# ESP32-C2 register map
Vendor: ESPRESSIF SYSTEMS (SHANGHAI) CO., LTD.; Series: ESP32 C-Series; File version: 11
CPU: RV32IMC r0p0, little endian, no MPU, no FPU, 0 interrupt priority bits
Address unit: 32 bits
Registers are 32-bit, read-write, reset 0x0 unless marked. A register's access mark holds for its fields unless they carry their own. Offsets are from the block's base; [hi:lo] are bit positions; {n}, {i} and the like mark numbered series.

## RTC_CNTL — Real-Time Clock Control
Base 0x60008000
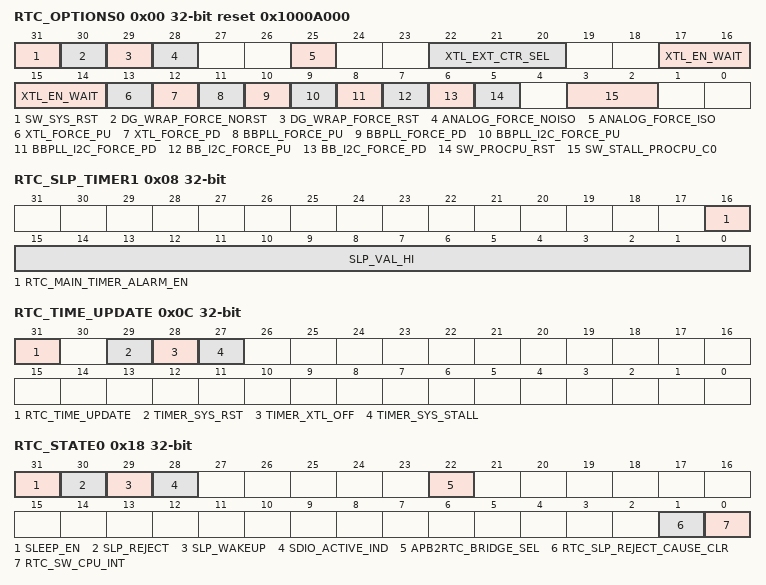
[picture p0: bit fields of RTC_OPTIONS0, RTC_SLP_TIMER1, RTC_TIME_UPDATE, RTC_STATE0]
0x00 RTC_OPTIONS0 reset 0x1000A000 — register description
  [31] SW_SYS_RST — SW system reset
  [30] DG_WRAP_FORCE_NORST — digital core force no reset in deep sleep
  [29] DG_WRAP_FORCE_RST — digital wrap force reset in deep sleep
  [28] ANALOG_FORCE_NOISO — Need add desc
  [25] ANALOG_FORCE_ISO — Need add desc
  [22:20] XTL_EXT_CTR_SEL — Need add desc
  [17:14] XTL_EN_WAIT — wait bias_sleep and current source wakeup
  [13] XTL_FORCE_PU — crystall force power up
  [12] XTL_FORCE_PD — crystall force power down
  [11] BBPLL_FORCE_PU — BB_PLL force power up
  [10] BBPLL_FORCE_PD — BB_PLL force power down
  [9] BBPLL_I2C_FORCE_PU — BB_PLL_I2C force power up
  [8] BBPLL_I2C_FORCE_PD — BB_PLL _I2C force power down
  [7] BB_I2C_FORCE_PU — BB_I2C force power up
  [6] BB_I2C_FORCE_PD — BB_I2C force power down
  [5] SW_PROCPU_RST — PRO CPU SW reset
  [3:2] SW_STALL_PROCPU_C0 — {reg_sw_stall_procpu_c1[5:0], reg_sw_stall_procpu_c0[1:0]} == 0x86 will stall PRO CPU
0x04 RTC_SLP_TIMER0 — register description
  [31:0] SLP_VAL_LO — Need add desc
0x08 RTC_SLP_TIMER1 — register description
  [16] RTC_MAIN_TIMER_ALARM_EN — timer alarm enable bit
  [15:0] SLP_VAL_HI — RTC sleep timer high 16 bits
0x0C RTC_TIME_UPDATE — register description
  [31] RTC_TIME_UPDATE — Set 1: to update register with RTC timer
  [29] TIMER_SYS_RST — enable to record system reset time
  [28] TIMER_XTL_OFF — Enable to record 40M XTAL OFF time
  [27] TIMER_SYS_STALL — Enable to record system stall time
0x10 RTC_TIME_LOW0 — register description
  [31:0] RTC_TIMER_VALUE0_LOW — RTC timer low 32 bits
0x14 RTC_TIME_HIGH0 — register description
  [15:0] RTC_TIMER_VALUE0_HIGH — RTC timer high 16 bits
0x18 RTC_STATE0 — register description
  [31] SLEEP_EN — sleep enable bit
  [30] SLP_REJECT — leep reject bit
  [29] SLP_WAKEUP — leep wakeup bit
  [28] SDIO_ACTIVE_IND — SDIO active indication
  [22] APB2RTC_BRIDGE_SEL — 1: APB to RTC using bridge
  [1] RTC_SLP_REJECT_CAUSE_CLR — clear rtc sleep reject cause
  [0] RTC_SW_CPU_INT — rtc software interrupt to main cpu
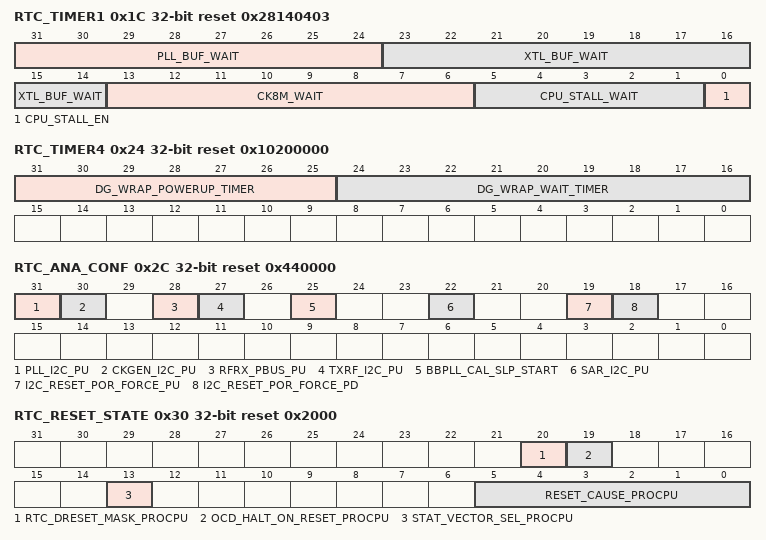
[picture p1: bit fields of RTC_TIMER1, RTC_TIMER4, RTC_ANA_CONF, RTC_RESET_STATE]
0x1C RTC_TIMER1 reset 0x28140403 — register description
  [31:24] PLL_BUF_WAIT — PLL wait cycles in slow_clk_rtc
  [23:14] XTL_BUF_WAIT — XTAL wait cycles in slow_clk_rtc
  [13:6] CK8M_WAIT — CK8M wait cycles in slow_clk_rtc
  [5:1] CPU_STALL_WAIT — CPU stall wait cycles in fast_clk_rtc
  [0] CPU_STALL_EN — CPU stall enable bit
0x20 RTC_TIMER2 reset 0x1000000 — register description
  [31:24] MIN_TIME_CK8M_OFF — minimal cycles in slow_clk_rtc for CK8M in power down state
0x24 RTC_TIMER4 reset 0x10200000 — register description
  [31:25] DG_WRAP_POWERUP_TIMER — Need add desc
  [24:16] DG_WRAP_WAIT_TIMER — Need add desc
0x28 RTC_TIMER5 reset 0x8000 — register description
  [15:8] MIN_SLP_VAL — minimal sleep cycles in slow_clk_rtc
0x2C RTC_ANA_CONF reset 0x440000 — register description
  [31] PLL_I2C_PU — Need add desc
  [30] CKGEN_I2C_PU — 1: CKGEN_I2C power up
  [28] RFRX_PBUS_PU — 1: RFRX_PBUS power up
  [27] TXRF_I2C_PU — 1: TXRF_I2C power up
  [25] BBPLL_CAL_SLP_START — start BBPLL calibration during sleep
  [22] SAR_I2C_PU — PLLA force power up
  [19] I2C_RESET_POR_FORCE_PU — Need add desc
  [18] I2C_RESET_POR_FORCE_PD — Need add desc
0x30 RTC_RESET_STATE reset 0x2000 — register description
  [20] RTC_DRESET_MASK_PROCPU — Need add desc
  [19] OCD_HALT_ON_RESET_PROCPU — PROCPU OcdHaltOnReset
  [13] STAT_VECTOR_SEL_PROCPU — PRO CPU state vector sel
  [5:0] RESET_CAUSE_PROCPU — reset cause of PRO CPU
0x34 RTC_WAKEUP_STATE reset 0x60000 — register description
  [31:15] RTC_WAKEUP_ENA — wakeup enable bitmap
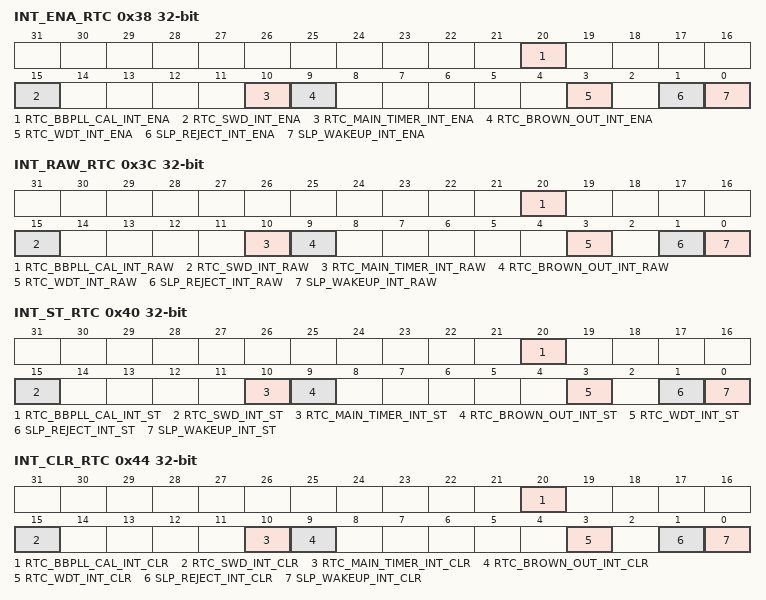
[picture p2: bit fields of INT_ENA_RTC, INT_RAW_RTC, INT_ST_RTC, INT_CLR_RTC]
0x38 INT_ENA_RTC access not given — register description
  [20] RTC_BBPLL_CAL_INT_ENA — Need add desc
  [15] RTC_SWD_INT_ENA — enable super watch dog interrupt
  [10] RTC_MAIN_TIMER_INT_ENA — enable RTC main timer interrupt
  [9] RTC_BROWN_OUT_INT_ENA — enable brown out interrupt
  [3] RTC_WDT_INT_ENA — enable RTC WDT interrupt
  [1] SLP_REJECT_INT_ENA — enable sleep reject interrupt
  [0] SLP_WAKEUP_INT_ENA — enable sleep wakeup interrupt
0x3C INT_RAW_RTC — register description
  [20] RTC_BBPLL_CAL_INT_RAW — Need add desc
  [15] RTC_SWD_INT_RAW — super watch dog interrupt raw
  [10] RTC_MAIN_TIMER_INT_RAW — RTC main timer interrupt raw
  [9] RTC_BROWN_OUT_INT_RAW — brown out interrupt raw
  [3] RTC_WDT_INT_RAW — RTC WDT interrupt raw
  [1] SLP_REJECT_INT_RAW — sleep reject interrupt raw
  [0] SLP_WAKEUP_INT_RAW — sleep wakeup interrupt raw
0x40 INT_ST_RTC — register description
  [20] RTC_BBPLL_CAL_INT_ST — Need add desc
  [15] RTC_SWD_INT_ST — super watch dog interrupt state
  [10] RTC_MAIN_TIMER_INT_ST — RTC main timer interrupt state
  [9] RTC_BROWN_OUT_INT_ST — brown out interrupt state
  [3] RTC_WDT_INT_ST — RTC WDT interrupt state
  [1] SLP_REJECT_INT_ST — sleep reject interrupt state
  [0] SLP_WAKEUP_INT_ST — sleep wakeup interrupt state
0x44 INT_CLR_RTC — register description
  [20] RTC_BBPLL_CAL_INT_CLR — Need add desc
  [15] RTC_SWD_INT_CLR — Clear super watch dog interrupt state
  [10] RTC_MAIN_TIMER_INT_CLR — Clear RTC main timer interrupt state
  [9] RTC_BROWN_OUT_INT_CLR — Clear brown out interrupt state
  [3] RTC_WDT_INT_CLR — Clear RTC WDT interrupt state
  [1] SLP_REJECT_INT_CLR — Clear sleep reject interrupt state
  [0] SLP_WAKEUP_INT_CLR — Clear sleep wakeup interrupt state
{0x48+4i} RTC_STORE{i} (i=0..3) — register description
  [31:0] RTC_SCRATCH{i} — Need add desc
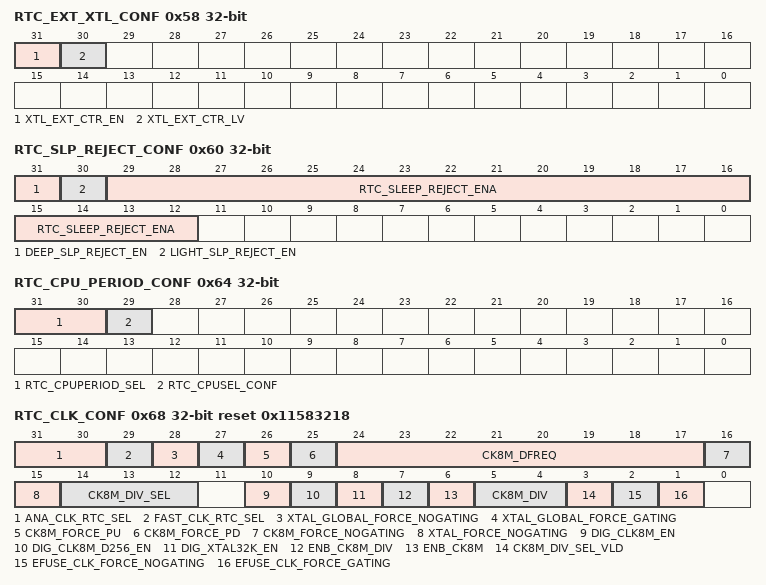
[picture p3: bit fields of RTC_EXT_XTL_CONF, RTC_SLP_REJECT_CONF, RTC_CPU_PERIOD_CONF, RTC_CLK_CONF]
0x58 RTC_EXT_XTL_CONF — register description
  [31] XTL_EXT_CTR_EN — Need add desc
  [30] XTL_EXT_CTR_LV — 0: power down XTAL at high level
0x5C RTC_EXT_WAKEUP_CONF — register description
  [31] GPIO_WAKEUP_FILTER — enable filter for gpio wakeup event
0x60 RTC_SLP_REJECT_CONF — register description
  [31] DEEP_SLP_REJECT_EN — enable reject for deep sleep
  [30] LIGHT_SLP_REJECT_EN — enable reject for light sleep
  [29:12] RTC_SLEEP_REJECT_ENA — sleep reject enable
0x64 RTC_CPU_PERIOD_CONF — register description
  [31:30] RTC_CPUPERIOD_SEL — Need add desc
  [29] RTC_CPUSEL_CONF — CPU sel option
0x68 RTC_CLK_CONF reset 0x11583218 — register description
  [31:30] ANA_CLK_RTC_SEL — Need add desc
  [29] FAST_CLK_RTC_SEL — fast_clk_rtc sel. 0: XTAL div 4
  [28] XTAL_GLOBAL_FORCE_NOGATING — Need add desc
  [27] XTAL_GLOBAL_FORCE_GATING — Need add desc
  [26] CK8M_FORCE_PU — CK8M force power up
  [25] CK8M_FORCE_PD — CK8M force power down
  [24:17] CK8M_DFREQ
  [16] CK8M_FORCE_NOGATING — CK8M force no gating during sleep
  [15] XTAL_FORCE_NOGATING — XTAL force no gating during sleep
  [14:12] CK8M_DIV_SEL — divider = reg_ck8m_div_sel + 1
  [10] DIG_CLK8M_EN — enable CK8M for digital core (no relationship with RTC core)
  [9] DIG_CLK8M_D256_EN — enable CK8M_D256_OUT for digital core (no relationship with RTC core)
  [8] DIG_XTAL32K_EN — enable CK_XTAL_32K for digital core (no relationship with RTC core)
  [7] ENB_CK8M_DIV — 1: CK8M_D256_OUT is actually CK8M
  [6] ENB_CK8M — disable CK8M and CK8M_D256_OUT
  [5:4] CK8M_DIV — CK8M_D256_OUT divider. 00: div128
  [3] CK8M_DIV_SEL_VLD — used to sync reg_ck8m_div_sel bus. Clear vld before set reg_ck8m_div_sel
  [2] EFUSE_CLK_FORCE_NOGATING — Need add desc
  [1] EFUSE_CLK_FORCE_GATING — Need add desc
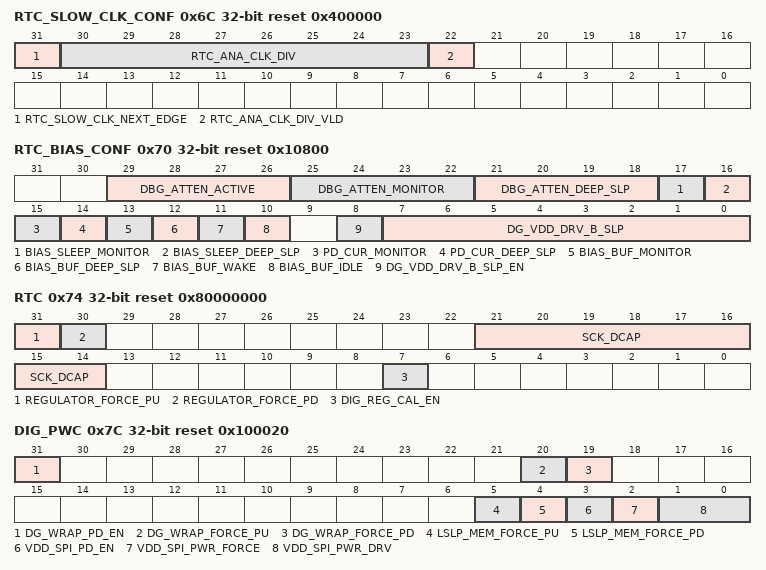
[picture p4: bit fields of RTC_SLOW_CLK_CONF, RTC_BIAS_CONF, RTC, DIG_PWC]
0x6C RTC_SLOW_CLK_CONF reset 0x400000 — register description
  [31] RTC_SLOW_CLK_NEXT_EDGE — Need add desc
  [30:23] RTC_ANA_CLK_DIV — Need add desc
  [22] RTC_ANA_CLK_DIV_VLD — used to sync div bus. clear vld before set reg_rtc_ana_clk_div
0x70 RTC_BIAS_CONF reset 0x10800 — register description
  [29:26] DBG_ATTEN_ACTIVE — Need add desc
  [25:22] DBG_ATTEN_MONITOR — DBG_ATTEN when rtc in active state
  [21:18] DBG_ATTEN_DEEP_SLP — DBG_ATTEN when rtc in sleep state
  [17] BIAS_SLEEP_MONITOR — bias_sleep when rtc in monitor state
  [16] BIAS_SLEEP_DEEP_SLP — bias_sleep when rtc in sleep_state
  [15] PD_CUR_MONITOR — xpd cur when rtc in monitor state
  [14] PD_CUR_DEEP_SLP — xpd cur when rtc in sleep_state
  [13] BIAS_BUF_MONITOR — Need add desc
  [12] BIAS_BUF_DEEP_SLP — Need add desc
  [11] BIAS_BUF_WAKE — Need add desc
  [10] BIAS_BUF_IDLE — Need add desc
  [8] DG_VDD_DRV_B_SLP_EN — Need add desc
  [7:0] DG_VDD_DRV_B_SLP — Need add desc
0x74 RTC reset 0x80000000 — register description
  [31] REGULATOR_FORCE_PU — Need add desc
  [30] REGULATOR_FORCE_PD — RTC_REG force power down (for RTC_REG power down means decrease the voltage to 0.8v or lower )
  [21:14] SCK_DCAP
  [7] DIG_REG_CAL_EN — Need add desc
0x78 RTC_PWC — register description
  [21] RTC_PAD_FORCE_HOLD
0x7C DIG_PWC reset 0x100020 — register description
  [31] DG_WRAP_PD_EN — Need add desc
  [20] DG_WRAP_FORCE_PU — digital core force power up
  [19] DG_WRAP_FORCE_PD — digital core force power down
  [5] LSLP_MEM_FORCE_PU — memories in digital core force no PD in sleep
  [4] LSLP_MEM_FORCE_PD — memories in digital core force PD in sleep
  [3] VDD_SPI_PD_EN — Need add desc
  [2] VDD_SPI_PWR_FORCE — Need add desc
  [1:0] VDD_SPI_PWR_DRV — Need add desc
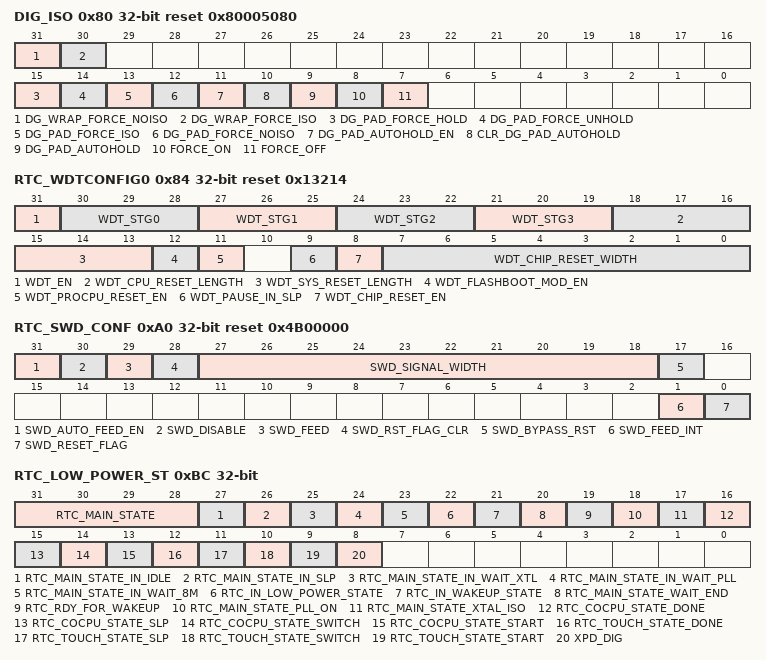
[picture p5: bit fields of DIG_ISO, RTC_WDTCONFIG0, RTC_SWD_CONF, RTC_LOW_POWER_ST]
0x80 DIG_ISO reset 0x80005080 — register description
  [31] DG_WRAP_FORCE_NOISO — Need add desc
  [30] DG_WRAP_FORCE_ISO — digital core force ISO
  [15] DG_PAD_FORCE_HOLD — digital pad force hold
  [14] DG_PAD_FORCE_UNHOLD — digital pad force un-hold
  [13] DG_PAD_FORCE_ISO — digital pad force ISO
  [12] DG_PAD_FORCE_NOISO — digital pad force no ISO
  [11] DG_PAD_AUTOHOLD_EN — digital pad enable auto-hold
  [10] CLR_DG_PAD_AUTOHOLD — wtite only register to clear digital pad auto-hold
  [9] DG_PAD_AUTOHOLD — read only register to indicate digital pad auto-hold status
  [8] FORCE_ON — Need add desc
  [7] FORCE_OFF — Need add desc
0x84 RTC_WDTCONFIG0 reset 0x13214 — register description
  [31] WDT_EN — Need add desc
  [30-3n:28-3n] WDT_STG{n} (n=0..3) — 1: interrupt stage en
  [18:16] WDT_CPU_RESET_LENGTH — CPU reset counter length
  [15:13] WDT_SYS_RESET_LENGTH — system reset counter length
  [12] WDT_FLASHBOOT_MOD_EN — enable WDT in flash boot
  [11] WDT_PROCPU_RESET_EN — enable WDT reset PRO CPU
  [9] WDT_PAUSE_IN_SLP — pause WDT in sleep
  [8] WDT_CHIP_RESET_EN — wdt reset whole chip enable
  [7:0] WDT_CHIP_RESET_WIDTH — chip reset siginal pulse width
0x88 RTC_WDTCONFIG1 reset 0x30D40 — register description
  [31:0] WDT_STG0_HOLD — Need add desc
0x8C RTC_WDTCONFIG2 reset 0x13880 — register description
  [31:0] WDT_STG1_HOLD — Need add desc
0x90 RTC_WDTCONFIG3 reset 0xFFF — register description
  [31:0] WDT_STG2_HOLD — Need add desc
0x94 RTC_WDTCONFIG4 reset 0xFFF — register description
  [31:0] WDT_STG3_HOLD — Need add desc
0x98 RTC_WDTFEED — register description
  [31] RTC_WDT_FEED — Need add desc
0x9C RTC_WDTWPROTECT — register description
  [31:0] WDT_WKEY — Need add desc
0xA0 RTC_SWD_CONF reset 0x4B00000 — register description
  [31] SWD_AUTO_FEED_EN — automatically feed swd when int comes
  [30] SWD_DISABLE — disabel SWD
  [29] SWD_FEED — Sw feed swd
  [28] SWD_RST_FLAG_CLR — reset swd reset flag
  [27:18] SWD_SIGNAL_WIDTH — adjust signal width send to swd
  [17] SWD_BYPASS_RST — Need add desc
  [1] SWD_FEED_INT — swd interrupt for feeding
  [0] SWD_RESET_FLAG
0xA4 RTC_SWD_WPROTECT — register description
  [31:0] SWD_WKEY — Need add desc
0xA8 RTC_SW_CPU_STALL — register description
  [31:26] SW_STALL_PROCPU_C1 — Need add desc
{0x9C+4i} RTC_STORE{i} (i=4..7) — register description
  [31:0] RTC_SCRATCH{i} — Need add desc
0xBC RTC_LOW_POWER_ST — register description
  [31:28] RTC_MAIN_STATE — rtc main state machine status
  [27] RTC_MAIN_STATE_IN_IDLE — rtc main state machine is in idle state
  [26] RTC_MAIN_STATE_IN_SLP — rtc main state machine is in sleep state
  [25] RTC_MAIN_STATE_IN_WAIT_XTL — rtc main state machine is in wait xtal state
  [24] RTC_MAIN_STATE_IN_WAIT_PLL — rtc main state machine is in wait pll state
  [23] RTC_MAIN_STATE_IN_WAIT_8M — rtc main state machine is in wait 8m state
  [22] RTC_IN_LOW_POWER_STATE — rtc main state machine is in the states of low power
  [21] RTC_IN_WAKEUP_STATE — rtc main state machine is in the states of wakeup process
  [20] RTC_MAIN_STATE_WAIT_END — rtc main state machine has been waited for some cycles
  [19] RTC_RDY_FOR_WAKEUP — rtc is ready to receive wake up trigger from wake up source
  [18] RTC_MAIN_STATE_PLL_ON — rtc main state machine is in states that pll should be running
  [17] RTC_MAIN_STATE_XTAL_ISO — no use any more
  [16] RTC_COCPU_STATE_DONE — ulp/cocpu is done
  [15] RTC_COCPU_STATE_SLP — ulp/cocpu is in sleep state
  [14] RTC_COCPU_STATE_SWITCH — ulp/cocpu is about to working. Switch rtc main state
  [13] RTC_COCPU_STATE_START — ulp/cocpu should start to work
  [12] RTC_TOUCH_STATE_DONE — touch is done
  [11] RTC_TOUCH_STATE_SLP — touch is in sleep state
  [10] RTC_TOUCH_STATE_SWITCH — touch is about to working. Switch rtc main state
  [9] RTC_TOUCH_STATE_START — touch should start to work
  [8] XPD_DIG — digital wrap power down
0xC0 RTC_DIAG0 — register description
  [31:0] RTC_LOW_POWER_DIAG1 — Need add desc
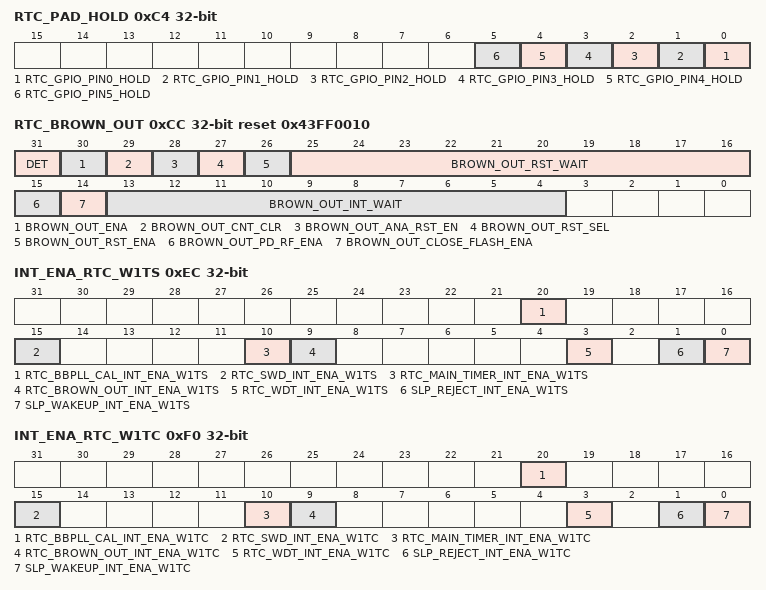
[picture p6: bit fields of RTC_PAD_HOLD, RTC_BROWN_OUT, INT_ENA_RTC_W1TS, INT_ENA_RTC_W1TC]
0xC4 RTC_PAD_HOLD — register description
  [n] RTC_GPIO_PIN{n}_HOLD (n=0..5) — Need add desc
0xC8 DIG_PAD_HOLD — register description
  [31:0] DIG_PAD_HOLD — Need add desc
0xCC RTC_BROWN_OUT reset 0x43FF0010 — register description
  [31] DET — Need add desc
  [30] BROWN_OUT_ENA — enable brown out
  [29] BROWN_OUT_CNT_CLR — clear brown out counter
  [28] BROWN_OUT_ANA_RST_EN — Need add desc
  [27] BROWN_OUT_RST_SEL — 1: 4-pos reset
  [26] BROWN_OUT_RST_ENA — enable brown out reset
  [25:16] BROWN_OUT_RST_WAIT — brown out reset wait cycles
  [15] BROWN_OUT_PD_RF_ENA — enable power down RF when brown out happens
  [14] BROWN_OUT_CLOSE_FLASH_ENA — enable close flash when brown out happens
  [13:4] BROWN_OUT_INT_WAIT — brown out interrupt wait cycles
0xD0 RTC_TIME_LOW1 — register description
  [31:0] RTC_TIMER_VALUE1_LOW — RTC timer low 32 bits
0xD4 RTC_TIME_HIGH1 — register description
  [15:0] RTC_TIMER_VALUE1_HIGH — RTC timer high 16 bits
0xD8 RTC_USB_CONF — register description
  [18] IO_MUX_RESET_DISABLE — Need add desc
0xDC RTC_SLP_REJECT_CAUSE — register description
  [17:0] REJECT_CAUSE — sleep reject cause
0xE0 RTC_OPTION1 — register description
  [0] FORCE_DOWNLOAD_BOOT — Need add desc
0xE4 RTC_SLP_WAKEUP_CAUSE — register description
  [16:0] WAKEUP_CAUSE — sleep wakeup cause
0xE8 RTC_ULP_CP_TIMER_1 reset 0xC800 — register description
  [31:8] ULP_CP_TIMER_SLP_CYCLE — sleep cycles for ULP-coprocessor timer
0xEC INT_ENA_RTC_W1TS — register description
  [20] RTC_BBPLL_CAL_INT_ENA_W1TS — Need add desc
  [15] RTC_SWD_INT_ENA_W1TS — enable super watch dog interrupt
  [10] RTC_MAIN_TIMER_INT_ENA_W1TS — enable RTC main timer interrupt
  [9] RTC_BROWN_OUT_INT_ENA_W1TS — enable brown out interrupt
  [3] RTC_WDT_INT_ENA_W1TS — enable RTC WDT interrupt
  [1] SLP_REJECT_INT_ENA_W1TS — enable sleep reject interrupt
  [0] SLP_WAKEUP_INT_ENA_W1TS — enable sleep wakeup interrupt
0xF0 INT_ENA_RTC_W1TC — register description
  [20] RTC_BBPLL_CAL_INT_ENA_W1TC — Need add desc
  [15] RTC_SWD_INT_ENA_W1TC — enable super watch dog interrupt
  [10] RTC_MAIN_TIMER_INT_ENA_W1TC — enable RTC main timer interrupt
  [9] RTC_BROWN_OUT_INT_ENA_W1TC — enable brown out interrupt
  [3] RTC_WDT_INT_ENA_W1TC — enable RTC WDT interrupt
  [1] SLP_REJECT_INT_ENA_W1TC — enable sleep reject interrupt
  [0] SLP_WAKEUP_INT_ENA_W1TC — enable sleep wakeup interrupt
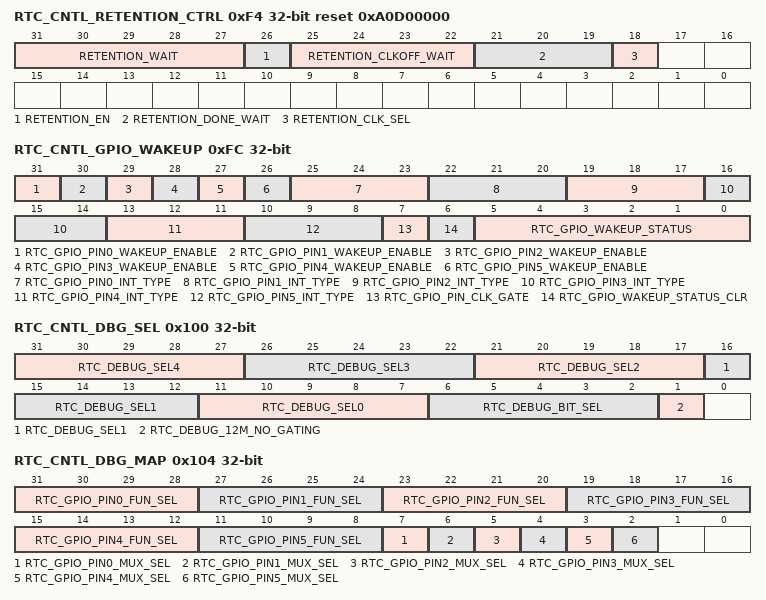
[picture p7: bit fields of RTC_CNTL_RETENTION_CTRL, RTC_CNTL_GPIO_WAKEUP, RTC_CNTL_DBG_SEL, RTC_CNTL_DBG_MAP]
0xF4 RTC_CNTL_RETENTION_CTRL reset 0xA0D00000 — register description
  [31:27] RETENTION_WAIT — wait cycles for rention operation
  [26] RETENTION_EN — Need add desc
  [25:22] RETENTION_CLKOFF_WAIT — Need add desc
  [21:19] RETENTION_DONE_WAIT — Need add desc
  [18] RETENTION_CLK_SEL — Need add desc
0xF8 RTC_FIB_SEL reset 0x7 — register description
  [2:0] RTC_FIB_SEL — select use analog fib signal
0xFC RTC_CNTL_GPIO_WAKEUP — register description
  [31-n] RTC_GPIO_PIN{n}_WAKEUP_ENABLE (n=0..5) — Need add desc
  [25-3n:23-3n] RTC_GPIO_PIN{n}_INT_TYPE (n=0..5) — Need add desc
  [7] RTC_GPIO_PIN_CLK_GATE — Need add desc
  [6] RTC_GPIO_WAKEUP_STATUS_CLR — Need add desc
  [5:0] RTC_GPIO_WAKEUP_STATUS — Need add desc
0x100 RTC_CNTL_DBG_SEL — register description
  [5n+11:5n+7] RTC_DEBUG_SEL{n} (n=0..4) — Need add desc
  [6:2] RTC_DEBUG_BIT_SEL — Need add desc
  [1] RTC_DEBUG_12M_NO_GATING — Need add desc
0x104 RTC_CNTL_DBG_MAP — register description
  [31-4n:28-4n] RTC_GPIO_PIN{n}_FUN_SEL (n=0..5) — Need add desc
  [7-n] RTC_GPIO_PIN{n}_MUX_SEL (n=0..5) — Need add desc
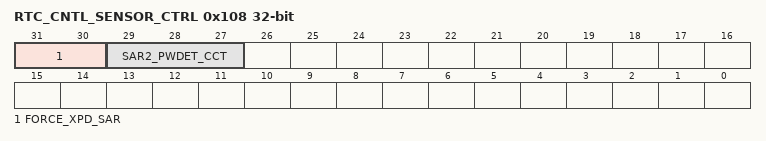
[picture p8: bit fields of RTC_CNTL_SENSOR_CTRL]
0x108 RTC_CNTL_SENSOR_CTRL — register description
  [31:30] FORCE_XPD_SAR — Need add desc
  [29:27] SAR2_PWDET_CCT — Need add desc
0x10C RTC_CNTL_DBG_SAR_SEL — register description
  [31:27] SAR_DEBUG_SEL — Need add desc
0x1FC RTC_CNTL_DATE reset 0x2107190 — register description
  [27:0] RTC_CNTL_DATE — Need add desc
